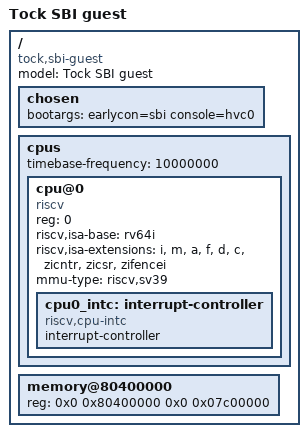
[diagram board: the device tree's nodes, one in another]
// Licensed under the Apache License, Version 2.0 or the MIT License.
// SPDX-License-Identifier: Apache-2.0 OR MIT
// Copyright Tock Contributors 2026.

// Device tree for the Linux SBI guest. It describes a single hart and the
// memory region Tock grants to the guest, and no devices: the console and
// timer are provided by Tock through the SBI.

/dts-v1/;

/ {
	#address-cells = <2>;
	#size-cells = <2>;
	compatible = "tock,sbi-guest";
	model = "Tock SBI guest";

	chosen {
		bootargs = "earlycon=sbi console=hvc0";
	};

	cpus {
		#address-cells = <1>;
		#size-cells = <0>;
		// The QEMU virt machine's mtime runs at 10 MHz.
		timebase-frequency = <10000000>;

		cpu@0 {
			device_type = "cpu";
			reg = <0>;
			status = "okay";
			compatible = "riscv";
			riscv,isa-base = "rv64i";
			riscv,isa-extensions = "i", "m", "a", "f", "d", "c",
					       "zicntr", "zicsr", "zifencei";
			mmu-type = "riscv,sv39";

			cpu0_intc: interrupt-controller {
				#interrupt-cells = <1>;
				interrupt-controller;
				compatible = "riscv,cpu-intc";
			};
		};
	};

	// Must match the region the board grants to the guest.
	memory@80400000 {
		device_type = "memory";
		reg = <0x0 0x80400000 0x0 0x07c00000>;
	};
};
